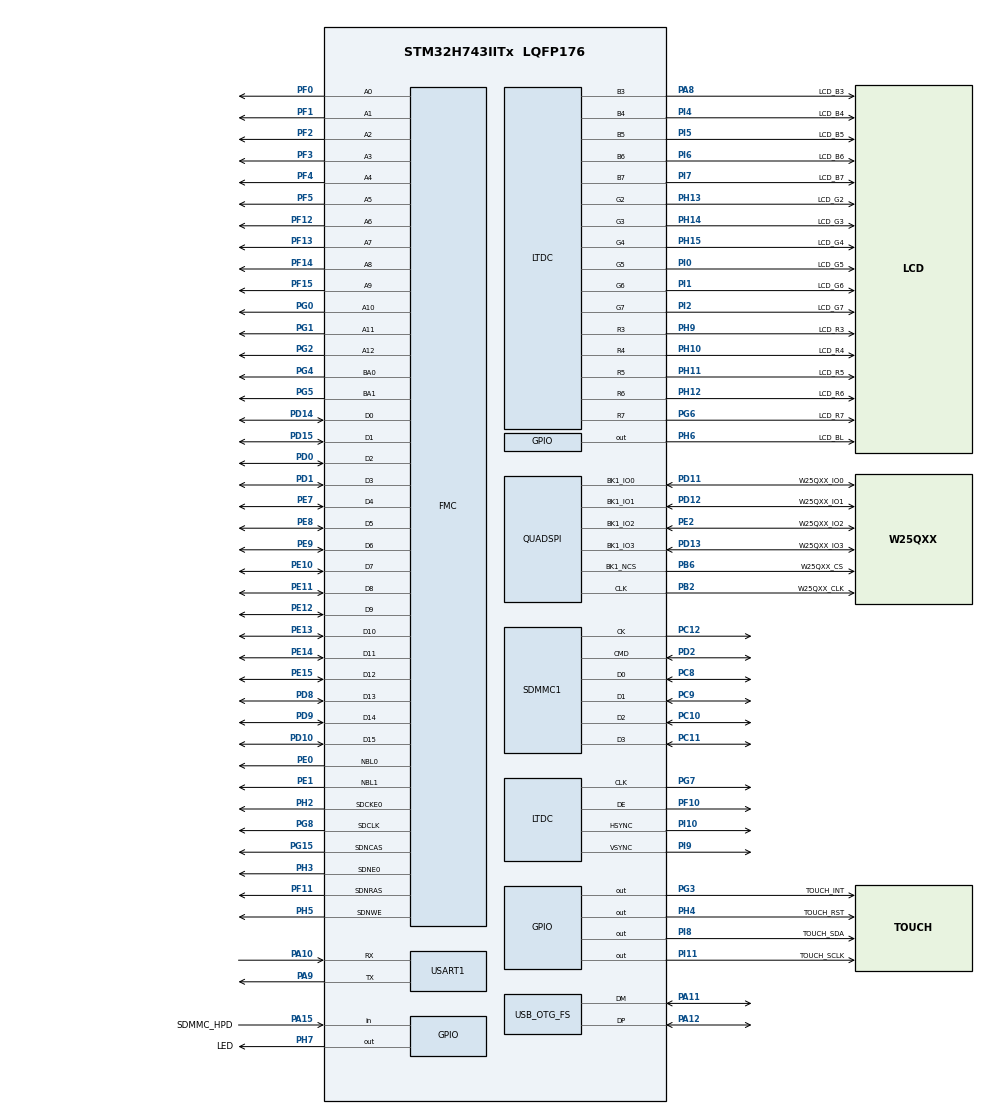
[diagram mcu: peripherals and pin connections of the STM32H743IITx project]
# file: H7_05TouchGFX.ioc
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CORTEX_M7.AccessPermission-Cortex_Memory_Protection_Unit_Region0_Settings=MPU_REGION_FULL_ACCESS
CORTEX_M7.BaseAddress-Cortex_Memory_Protection_Unit_Region0_Settings=0x38000000
CORTEX_M7.CPU_DCache=Enabled
CORTEX_M7.CPU_ICache=Enabled
CORTEX_M7.DisableExec-Cortex_Memory_Protection_Unit_Region0_Settings=MPU_INSTRUCTION_ACCESS_ENABLE
CORTEX_M7.Enable-Cortex_Memory_Protection_Unit_Region0_Settings=MPU_REGION_ENABLE
CORTEX_M7.IsCacheable-Cortex_Memory_Protection_Unit_Region0_Settings=MPU_ACCESS_CACHEABLE
CORTEX_M7.IsShareable-Cortex_Memory_Protection_Unit_Region0_Settings=MPU_ACCESS_SHAREABLE
CORTEX_M7.MPU_Control=MPU_PRIVILEGED_DEFAULT
CORTEX_M7.Size-Cortex_Memory_Protection_Unit_Region0_Settings=MPU_REGION_SIZE_64KB
DMA2D.ColorMode=DMA2D_OUTPUT_RGB565
DMA2D.InputColorModeForeground=DMA2D_INPUT_RGB565
DMA2D.Mode=DMA2D_M2M
Dma.Request0=USART1_RX
Dma.USART1_RX.0.Direction=DMA_PERIPH_TO_MEMORY
Dma.USART1_RX.0.EventEnable=DISABLE
Dma.USART1_RX.0.FIFOMode=DMA_FIFOMODE_DISABLE
Dma.USART1_RX.0.Instance=DMA1_Stream0
Dma.USART1_RX.0.MemDataAlignment=DMA_MDATAALIGN_BYTE
Dma.USART1_RX.0.MemInc=DMA_MINC_ENABLE
Dma.USART1_RX.0.Mode=DMA_NORMAL
Dma.USART1_RX.0.PeriphDataAlignment=DMA_PDATAALIGN_BYTE
Dma.USART1_RX.0.PeriphInc=DMA_PINC_DISABLE
Dma.USART1_RX.0.Polarity=HAL_DMAMUX_REQ_GEN_RISING
Dma.USART1_RX.0.Priority=DMA_PRIORITY_LOW
Dma.USART1_RX.0.RequestNumber=1
Dma.USART1_RX.0.SignalID=NONE
Dma.USART1_RX.0.SyncEnable=DISABLE
Dma.USART1_RX.0.SyncPolarity=HAL_DMAMUX_SYNC_NO_EVENT
Dma.USART1_RX.0.SyncRequestNumber=1
Dma.USART1_RX.0.SyncSignalID=NONE
FATFS.BSP.number=1
FATFS._CODE_PAGE=437
FATFS._FS_LOCK=0
FATFS._FS_NORTC=1
FATFS._MAX_SS=4096
FATFS._NORTC_MDAY=5
FATFS._NORTC_MON=1
FATFS._NORTC_YEAR=2017
FATFS._USE_FASTSEEK=0
FATFS._USE_LFN=2
FATFS._USE_STRFUNC=0
FATFS._VOLUMES=1
FATFS0.BSP.STBoard=false
FATFS0.BSP.api=Unknown
FATFS0.BSP.i2caddr=0
FATFS0.BSP.instance=PA15 (JTDI)
FATFS0.BSP.ip=GPIO
FATFS0.BSP.mode=Input
FATFS0.BSP.name=Detect_SDIO
FATFS0.BSP.solution=PA15 (JTDI)
FMC.BankMapConfig=FMC_SWAPBMAP_DISABLE
FMC.CASLatency1=FMC_SDRAM_CAS_LATENCY_3
FMC.ColumnBitsNumber1=FMC_SDRAM_COLUMN_BITS_NUM_9
FMC.ExitSelfRefreshDelay1=7
FMC.LoadToActiveDelay1=2
FMC.RCDDelay1=2
FMC.RPDelay1=2
FMC.ReadBurst1=FMC_SDRAM_RBURST_ENABLE
FMC.ReadPipeDelay1=FMC_SDRAM_RPIPE_DELAY_1
FMC.RowCycleDelay1=7
FMC.SDClockPeriod1=FMC_SDRAM_CLOCK_PERIOD_2
FMC.SelfRefreshTime1=4
FMC.WriteRecoveryTime1=3
FREERTOS.Tasks01=defaultTask,24,5120,StartDefaultTask,Default,NULL,Dynamic,NULL,NULL
FREERTOS.configGENERATE_RUN_TIME_STATS=1
FREERTOS.configRECORD_STACK_HIGH_ADDRESS=1
FREERTOS.configTOTAL_HEAP_SIZE=131072
FREERTOS.configUSE_NEWLIB_REENTRANT=1
FREERTOS.configUSE_STATS_FORMATTING_FUNCTIONS=1
LTDC.ActiveH=480
LTDC.ActiveW=800
LTDC.Alpha_L0=0xFF
LTDC.BlendingFactor1_L0=LTDC_BLENDING_FACTOR1_CA
LTDC.BlendingFactor2_L0=LTDC_BLENDING_FACTOR2_CA
LTDC.FBStartAdress_L0=0xC0000000
LTDC.HBP=80
LTDC.HFP=200
LTDC.HSync=1
LTDC.ImageHeight_L0=480
LTDC.ImageWidth_L0=800
LTDC.Layers=0
LTDC.PixelFormat_L0=LTDC_PIXEL_FORMAT_RGB565
LTDC.VBP=40
LTDC.VFP=22
LTDC.VSync=1
LTDC.WindowX1_L0=800
LTDC.WindowY1_L0=480
Mcu.Family=STM32H7
Mcu.Name=STM32H743IITx
Mcu.Package=LQFP176
NVIC.DMA1_Stream0_IRQn=true\:5\:0\:false\:false\:true\:true\:false\:true
NVIC.LTDC_IRQn=true\:5\:0\:false\:false\:true\:true\:true\:true
NVIC.OTG_FS_IRQn=true\:5\:0\:false\:false\:true\:true\:true\:true
NVIC.PriorityGroup=NVIC_PRIORITYGROUP_4
NVIC.TIM6_DAC_IRQn=true\:5\:0\:false\:false\:false\:true\:true\:true
NVIC.TIM7_IRQn=true\:15\:0\:false\:false\:true\:false\:false\:true
NVIC.TimeBase=TIM7_IRQn
NVIC.TimeBaseIP=TIM7
NVIC.USART1_IRQn=true\:6\:0\:true\:false\:false\:true\:true\:false
PA10.Mode=Asynchronous
PA10.Signal=USART1_RX
PA11.Mode=Device_Only
PA11.Signal=USB_OTG_FS_DM
PA12.Mode=Device_Only
PA12.Signal=USB_OTG_FS_DP
PA13\ (JTMS/SWDIO).Mode=Serial_Wire
PA13\ (JTMS/SWDIO).Signal=DEBUG_JTMS-SWDIO
PA14\ (JTCK/SWCLK).Mode=Serial_Wire
PA14\ (JTCK/SWCLK).Signal=DEBUG_JTCK-SWCLK
PA15\ (JTDI).GPIO_Label=SDMMC_HPD
PA15\ (JTDI).GPIO_PuPd=GPIO_PULLDOWN
PA15\ (JTDI).Signal=GPIO_Input
PA2.GPIO_Label=LCD_R1
PA2.GPIO_Speed=GPIO_SPEED_FREQ_VERY_HIGH
PA2.Signal=LTDC_R1
PA8.GPIO_Label=LCD_B3
PA8.GPIO_Speed=GPIO_SPEED_FREQ_VERY_HIGH
PA8.Mode=RGB565
PA8.Signal=LTDC_B3
PA9.Mode=Asynchronous
PA9.Signal=USART1_TX
PB2.GPIO_Label=W25QXX_CLK
PB2.GPIO_Speed=GPIO_SPEED_FREQ_VERY_HIGH
PB2.Mode=Single Bank 1
PB2.Signal=QUADSPI_CLK
PB6.GPIO_FM6=SYSCFG_PMCR_I2C_PB6_FMP
PB6.GPIO_Label=W25QXX_CS
PB6.GPIO_Speed=GPIO_SPEED_FREQ_VERY_HIGH
PB6.Mode=Single Bank 1
PB6.Signal=QUADSPI_BK1_NCS
PC10.Mode=SD_4_bits_Wide_bus
PC10.Signal=SDMMC1_D2
PC11.Mode=SD_4_bits_Wide_bus
PC11.Signal=SDMMC1_D3
PC12.Mode=SD_4_bits_Wide_bus
PC12.Signal=SDMMC1_CK
PC14-OSC32_IN\ (OSC32_IN).Mode=LSE-External-Oscillator
PC14-OSC32_IN\ (OSC32_IN).Signal=RCC_OSC32_IN
PC15-OSC32_OUT\ (OSC32_OUT).Mode=LSE-External-Oscillator
PC15-OSC32_OUT\ (OSC32_OUT).Signal=RCC_OSC32_OUT
PC8.Mode=SD_4_bits_Wide_bus
PC8.Signal=SDMMC1_D0
PC9.Mode=SD_4_bits_Wide_bus
PC9.Signal=SDMMC1_D1
PD0.Signal=FMC_D2_DA2
PD1.Signal=FMC_D3_DA3
PD10.Signal=FMC_D15_DA15
PD11.GPIO_Label=W25QXX_IO0
PD11.GPIO_Speed=GPIO_SPEED_FREQ_VERY_HIGH
PD11.Mode=Single Bank 1
PD11.Signal=QUADSPI_BK1_IO0
PD12.GPIO_Label=W25QXX_IO1
PD12.GPIO_Speed=GPIO_SPEED_FREQ_VERY_HIGH
PD12.Mode=Single Bank 1
PD12.Signal=QUADSPI_BK1_IO1
PD13.GPIO_Label=W25QXX_IO3
PD13.GPIO_Speed=GPIO_SPEED_FREQ_VERY_HIGH
PD13.Mode=Single Bank 1
PD13.Signal=QUADSPI_BK1_IO3
PD14.Signal=FMC_D0_DA0
PD15.Signal=FMC_D1_DA1
PD2.Mode=SD_4_bits_Wide_bus
PD2.Signal=SDMMC1_CMD
PD6.GPIO_Label=LCD_B2
PD6.GPIO_Speed=GPIO_SPEED_FREQ_VERY_HIGH
PD6.Signal=LTDC_B2
PD8.Signal=FMC_D13_DA13
PD9.Signal=FMC_D14_DA14
PE0.GPIO_Speed_High_Default=GPIO_SPEED_FREQ_VERY_HIGH
PE0.Signal=FMC_NBL0
PE1.Signal=FMC_NBL1
PE10.Signal=FMC_D7_DA7
PE11.Signal=FMC_D8_DA8
PE12.Signal=FMC_D9_DA9
PE13.Signal=FMC_D10_DA10
PE14.Signal=FMC_D11_DA11
PE15.Signal=FMC_D12_DA12
PE2.GPIO_Label=W25QXX_IO2
PE2.GPIO_Speed=GPIO_SPEED_FREQ_VERY_HIGH
PE2.Mode=Single Bank 1
PE2.Signal=QUADSPI_BK1_IO2
PE5.GPIO_Label=LCD_G0
PE5.GPIO_Speed=GPIO_SPEED_FREQ_VERY_HIGH
PE5.Signal=LTDC_G0
PE6.GPIO_Label=LCD_G1
PE6.GPIO_Speed=GPIO_SPEED_FREQ_VERY_HIGH
PE6.PinAttribute=Free
PE6.Signal=LTDC_G1
PE7.Signal=FMC_D4_DA4
PE8.Signal=FMC_D5_DA5
PE9.Signal=FMC_D6_DA6
PF0.Signal=FMC_A0
PF1.Signal=FMC_A1
PF10.GPIO_Speed=GPIO_SPEED_FREQ_VERY_HIGH
PF10.Mode=RGB565
PF10.Signal=LTDC_DE
PF11.Signal=FMC_SDNRAS
PF12.Signal=FMC_A6
PF13.Signal=FMC_A7
PF14.Signal=FMC_A8
PF15.Signal=FMC_A9
PF2.Signal=FMC_A2
PF3.Signal=FMC_A3
PF4.Signal=FMC_A4
PF5.Signal=FMC_A5
PG0.Signal=FMC_A10
PG1.Signal=FMC_A11
PG12.GPIO_Label=LCD_B1
PG12.GPIO_Speed=GPIO_SPEED_FREQ_VERY_HIGH
PG12.Signal=LTDC_B1
PG13.GPIO_Label=LCD_R0
PG13.GPIO_Speed=GPIO_SPEED_FREQ_VERY_HIGH
PG13.Signal=LTDC_R0
PG14.GPIO_Label=LCD_B0
PG14.GPIO_Speed=GPIO_SPEED_FREQ_VERY_HIGH
PG14.Signal=LTDC_B0
PG15.Signal=FMC_SDNCAS
PG2.Signal=FMC_A12
PG3.GPIO_Label=TOUCH_INT
PG3.GPIO_Speed=GPIO_SPEED_FREQ_LOW
PG3.Signal=GPIO_Output
PG4.Signal=FMC_A14_BA0
PG5.Signal=FMC_A15_BA1
PG6.GPIO_Label=LCD_R7
PG6.GPIO_Speed=GPIO_SPEED_FREQ_VERY_HIGH
PG6.Mode=RGB565
PG6.Signal=LTDC_R7
PG7.GPIO_Speed=GPIO_SPEED_FREQ_VERY_HIGH
PG7.Mode=RGB565
PG7.Signal=LTDC_CLK
PG8.Signal=FMC_SDCLK
PH0-OSC_IN\ (PH0).Mode=HSE-External-Oscillator
PH0-OSC_IN\ (PH0).Signal=RCC_OSC_IN
PH1-OSC_OUT\ (PH1).Mode=HSE-External-Oscillator
PH1-OSC_OUT\ (PH1).Signal=RCC_OSC_OUT
PH10.GPIO_Label=LCD_R4
PH10.GPIO_Speed=GPIO_SPEED_FREQ_VERY_HIGH
PH10.Mode=RGB565
PH10.Signal=LTDC_R4
PH11.GPIO_Label=LCD_R5
PH11.GPIO_Speed=GPIO_SPEED_FREQ_VERY_HIGH
PH11.Mode=RGB565
PH11.Signal=LTDC_R5
PH12.GPIO_Label=LCD_R6
PH12.GPIO_Speed=GPIO_SPEED_FREQ_VERY_HIGH
PH12.Mode=RGB565
PH12.Signal=LTDC_R6
PH13.GPIO_Label=LCD_G2
PH13.GPIO_Speed=GPIO_SPEED_FREQ_VERY_HIGH
PH13.Mode=RGB565
PH13.Signal=LTDC_G2
PH14.GPIO_Label=LCD_G3
PH14.GPIO_Speed=GPIO_SPEED_FREQ_VERY_HIGH
PH14.Mode=RGB565
PH14.Signal=LTDC_G3
PH15.GPIO_Label=LCD_G4
PH15.GPIO_Speed=GPIO_SPEED_FREQ_VERY_HIGH
PH15.Mode=RGB565
PH15.Signal=LTDC_G4
PH2.Mode=SdramChipSelect1_1
PH2.Signal=FMC_SDCKE0
PH3.Mode=SdramChipSelect1_1
PH3.Signal=FMC_SDNE0
PH4.GPIO_Label=TOUCH_RST
PH4.GPIO_PuPd=GPIO_NOPULL
PH4.GPIO_Speed=GPIO_SPEED_FREQ_LOW
PH4.PinState=GPIO_PIN_SET
PH4.Signal=GPIO_Output
PH5.Signal=FMC_SDNWE
PH6.GPIO_Label=LCD_BL
PH6.GPIO_PuPd=GPIO_NOPULL
PH6.PinState=GPIO_PIN_RESET
PH6.Signal=GPIO_Output
PH7.GPIO_Label=LED
PH7.GPIO_PuPd=GPIO_PULLUP
PH7.GPIO_Speed=GPIO_SPEED_FREQ_VERY_HIGH
PH7.Signal=GPIO_Output
PH8.GPIO_Label=LCD_R2
PH8.GPIO_Speed=GPIO_SPEED_FREQ_VERY_HIGH
PH8.Signal=LTDC_R2
PH9.GPIO_Label=LCD_R3
PH9.GPIO_Speed=GPIO_SPEED_FREQ_VERY_HIGH
PH9.Mode=RGB565
PH9.Signal=LTDC_R3
PI0.GPIO_Label=LCD_G5
PI0.GPIO_Speed=GPIO_SPEED_FREQ_VERY_HIGH
PI0.Mode=RGB565
PI0.Signal=LTDC_G5
PI1.GPIO_Label=LCD_G6
PI1.GPIO_Speed=GPIO_SPEED_FREQ_VERY_HIGH
PI1.Mode=RGB565
PI1.Signal=LTDC_G6
PI10.GPIO_Speed=GPIO_SPEED_FREQ_VERY_HIGH
PI10.Mode=RGB565
PI10.Signal=LTDC_HSYNC
PI11.GPIO_Label=TOUCH_SCLK
PI11.GPIO_ModeDefaultOutputPP=GPIO_MODE_OUTPUT_OD
PI11.GPIO_Speed=GPIO_SPEED_FREQ_LOW
PI11.Signal=GPIO_Output
PI2.GPIO_Label=LCD_G7
PI2.GPIO_Speed=GPIO_SPEED_FREQ_VERY_HIGH
PI2.Mode=RGB565
PI2.Signal=LTDC_G7
PI4.GPIO_Label=LCD_B4
PI4.GPIO_Speed=GPIO_SPEED_FREQ_VERY_HIGH
PI4.Mode=RGB565
PI4.Signal=LTDC_B4
PI5.GPIO_Label=LCD_B5
PI5.GPIO_Speed=GPIO_SPEED_FREQ_VERY_HIGH
PI5.Mode=RGB565
PI5.Signal=LTDC_B5
PI6.GPIO_Label=LCD_B6
PI6.GPIO_Speed=GPIO_SPEED_FREQ_VERY_HIGH
PI6.Mode=RGB565
PI6.Signal=LTDC_B6
PI7.GPIO_Label=LCD_B7
PI7.GPIO_Speed=GPIO_SPEED_FREQ_VERY_HIGH
PI7.Mode=RGB565
PI7.Signal=LTDC_B7
PI8.GPIO_Label=TOUCH_SDA
PI8.GPIO_ModeDefaultOutputPP=GPIO_MODE_OUTPUT_OD
PI8.GPIO_Speed=GPIO_SPEED_FREQ_LOW
PI8.PinAttribute=Free
PI8.Signal=GPIO_Output
PI9.GPIO_Speed=GPIO_SPEED_FREQ_VERY_HIGH
PI9.Mode=RGB565
PI9.Signal=LTDC_VSYNC
ProjectManager.HeapSize=0x2000
ProjectManager.StackSize=0x4000
ProjectManager.TargetToolchain=STM32CubeIDE
QUADSPI.ClockMode=QSPI_CLOCK_MODE_3
QUADSPI.ClockPrescaler=1
QUADSPI.FifoThreshold=32
QUADSPI.FlashSize=22
QUADSPI.SampleShifting=QSPI_SAMPLE_SHIFTING_HALFCYCLE
RCC.ADCFreq_Value=240000000
RCC.APB1Freq_Value=64000000
RCC.APB2Freq_Value=64000000
RCC.APB3Freq_Value=64000000
RCC.APB4Freq_Value=64000000
RCC.CortexFreq_Value=256000000
RCC.D1PPRE=RCC_APB3_DIV2
RCC.D2PPRE1=RCC_APB1_DIV2
RCC.D2PPRE2=RCC_APB2_DIV2
RCC.D3PPRE=RCC_APB4_DIV2
RCC.DIVM1=25
RCC.DIVM2=5
RCC.DIVM3=25
RCC.DIVN1=512
RCC.DIVN2=96
RCC.DIVN3=330
RCC.DIVQ1=16
RCC.DIVQ2=10
RCC.DIVR1=8
RCC.DIVR2=4
RCC.DIVR3=10
RCC.FMCCLockSelection=RCC_FMCCLKSOURCE_PLL2
RCC.HCLKFreq_Value=128000000
RCC.HPRE=RCC_HCLK_DIV2
RCC.PLL2FRACN=0
RCC.PLL3FRACN=0
RCC.PLL3_VCO_SEL=RCC_PLL3VCOMEDIUM
RCC.PLLSourceVirtual=RCC_PLLSOURCE_HSE
RCC.SYSCLKFreq_VALUE=256000000
RCC.SYSCLKSource=RCC_SYSCLKSOURCE_PLLCLK
RCC.USART16CLockSelection=RCC_USART16CLKSOURCE_PLL2
RCC.USBCLockSelection=RCC_USBCLKSOURCE_HSI48
RCC.USBFreq_Value=48000000
SDMMC1.ClockDiv=6
SH.FMC_A0.0=FMC_A0,13b-sda1
SH.FMC_A1.0=FMC_A1,13b-sda1
SH.FMC_A10.0=FMC_A10,13b-sda1
SH.FMC_A11.0=FMC_A11,13b-sda1
SH.FMC_A12.0=FMC_A12,13b-sda1
SH.FMC_A14_BA0.0=FMC_BA0,FourSdramBanks1
SH.FMC_A15_BA1.0=FMC_BA1,FourSdramBanks1
SH.FMC_A2.0=FMC_A2,13b-sda1
SH.FMC_A3.0=FMC_A3,13b-sda1
SH.FMC_A4.0=FMC_A4,13b-sda1
SH.FMC_A5.0=FMC_A5,13b-sda1
SH.FMC_A6.0=FMC_A6,13b-sda1
SH.FMC_A7.0=FMC_A7,13b-sda1
SH.FMC_A8.0=FMC_A8,13b-sda1
SH.FMC_A9.0=FMC_A9,13b-sda1
SH.FMC_D0_DA0.0=FMC_D0,sd-16b-d1
SH.FMC_D10_DA10.0=FMC_D10,sd-16b-d1
SH.FMC_D11_DA11.0=FMC_D11,sd-16b-d1
SH.FMC_D12_DA12.0=FMC_D12,sd-16b-d1
SH.FMC_D13_DA13.0=FMC_D13,sd-16b-d1
SH.FMC_D14_DA14.0=FMC_D14,sd-16b-d1
SH.FMC_D15_DA15.0=FMC_D15,sd-16b-d1
SH.FMC_D1_DA1.0=FMC_D1,sd-16b-d1
SH.FMC_D2_DA2.0=FMC_D2,sd-16b-d1
SH.FMC_D3_DA3.0=FMC_D3,sd-16b-d1
SH.FMC_D4_DA4.0=FMC_D4,sd-16b-d1
SH.FMC_D5_DA5.0=FMC_D5,sd-16b-d1
SH.FMC_D6_DA6.0=FMC_D6,sd-16b-d1
SH.FMC_D7_DA7.0=FMC_D7,sd-16b-d1
SH.FMC_D8_DA8.0=FMC_D8,sd-16b-d1
SH.FMC_D9_DA9.0=FMC_D9,sd-16b-d1
SH.FMC_NBL0.0=FMC_NBL0,Sd2ByteEnable1
SH.FMC_NBL1.0=FMC_NBL1,Sd2ByteEnable1
SH.FMC_SDCLK.0=FMC_SDCLK,13b-sda1
SH.FMC_SDNCAS.0=FMC_SDNCAS,13b-sda1
SH.FMC_SDNRAS.0=FMC_SDNRAS,13b-sda1
SH.FMC_SDNWE.0=FMC_SDNWE,13b-sda1
STMicroelectronics.X-CUBE-TOUCHGFX.4.18.0.ApplicationCcGraphicsJjApplication=TouchGFXOoGenerator
STMicroelectronics.X-CUBE-TOUCHGFX.4.18.0.tgfx_address1=0xC0000000
STMicroelectronics.X-CUBE-TOUCHGFX.4.18.0.tgfx_address2=0xC00BB800
STMicroelectronics.X-CUBE-TOUCHGFX.4.18.0.tgfx_buffering_strategy=Double
STMicroelectronics.X-CUBE-TOUCHGFX.4.18.0.tgfx_display_interface=disp_ltdc
STMicroelectronics.X-CUBE-TOUCHGFX.4.18.0.tgfx_hardware_accelerator=dma_2d
STMicroelectronics.X-CUBE-TOUCHGFX.4.18.0.tgfx_location=By Address
STMicroelectronics.X-CUBE-TOUCHGFX.4.18.0.tgfx_vsync=vsync_ltdc
STMicroelectronics.X-CUBE-TOUCHGFX.4.18.0_IsPackSelfContextualization=true
TIM6.Period=100-1
TIM6.Prescaler=128-1
USART1.VirtualMode-Asynchronous=VM_ASYNC
USB_DEVICE.CLASS_NAME_FS=MSC
USB_DEVICE.MSC_MEDIA_PACKET-MSC_FS=4096
USB_DEVICE.PID_MSC_FS=22313
USB_DEVICE.USBD_DEBUG_LEVEL-MSC_FS=3
USB_DEVICE.USBD_MAX_NUM_CONFIGURATION-MSC_FS=1
USB_DEVICE.USBD_MAX_NUM_INTERFACES-MSC_FS=1
USB_DEVICE.VID-MSC_FS=1154
USB_DEVICE.VirtualMode-MSC_FS=Msc
USB_DEVICE.VirtualModeFS=Msc_FS
USB_OTG_FS.VirtualMode=Device_Only
VP_CRC_VS_CRC.Mode=CRC_Activate
VP_DMA2D_VS_DMA2D.Mode=DMA2D_Activate
VP_FATFS_VS_SDIO.Mode=SDIO
VP_FREERTOS_VS_CMSIS_V2.Mode=CMSIS_V2
VP_STMicroelectronics.X-CUBE-TOUCHGFX_VS_GraphicsJjApplication_4.18.0.Mode=GraphicsJjApplication
VP_SYS_VS_tim7.Mode=TIM7
VP_TIM12_VS_ClockSourceINT.Mode=Internal
VP_TIM6_VS_ClockSourceINT.Mode=Enable_Timer
VP_USB_DEVICE_VS_USB_DEVICE_MSC_FS.Mode=MSC_FS
board=custom

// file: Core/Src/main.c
/* USER CODE BEGIN Header */
/**
  ******************************************************************************
  * @file           : main.c
  * @brief          : Main program body
  ******************************************************************************
  * @attention
  *
  * <h2><center>&copy; Copyright (c) 2021 STMicroelectronics.
  * All rights reserved.</center></h2>
  *
  * This software component is licensed by ST under BSD 3-Clause license,
  * the "License"; You may not use this file except in compliance with the
  * License. You may obtain a copy of the License at:
  *                        opensource.org/licenses/BSD-3-Clause
  *
  ******************************************************************************
  */
/* USER CODE END Header */
#include "main.h"
#include "cmsis_os.h"
#include "crc.h"
#include "dma.h"
#include "dma2d.h"
#include "fatfs.h"
#include "ltdc.h"
#include "quadspi.h"
#include "sdmmc.h"
#include "tim.h"
#include "usart.h"
#include "usb_device.h"
#include "gpio.h"
#include "fmc.h"
#include "app_touchgfx.h"

/* USER CODE BEGIN Includes */
#include "stdio.h"
#include "lcd_rgb.h"
#include "string.h"
#include "touch_800x480.h"
#include "W25QXX.h"
#include "usart.h"
/* USER CODE END Includes */

void SystemClock_Config(void);
void PeriphCommonClock_Config(void);
static void MPU_Config(void);
void MX_FREERTOS_Init(void);
/* USER CODE BEGIN PFP */
/********************************************** 变量定义 *******************************************/

FRESULT 	MyFile_Res;    // 操作结果
FATFS 		SD_FatFs; 		// 文件系统对象
char SDPath[4];			// SD卡逻辑驱动路径
FATFS 		sFLASH_FatFs; 					// 文件系统对象
BYTE 			sFLASH_ReadBuffer[1024];	//要读出的数据

/**************************************************************************************************/

//	函数：FatFs_Check
//	功能：进行FatFs文件系统的挂载
//
FIL MyFile;
void FatFs_Check(void)	//判断FatFs是否挂载成功，若没有创建FatFs则格式化SD卡
{
	BYTE work[_MAX_SS];

	FATFS_LinkDriver(&SD_Driver, SDPath);		// 初始化驱动
	MyFile_Res = f_mount(&SD_FatFs,"0:",1);	//	挂载SD卡

	if (MyFile_Res == FR_OK)	//判断是否挂载成功
	{
		printf("SD文件系统挂载成功\r\n");
	}
	else
	{
		printf("SD卡还未创建文件系统，即将格式化\r\n");

		MyFile_Res = f_mkfs("0:",FM_FAT32,0,work,sizeof work);		//格式化SD卡，FAT32，簇默认大小16K

		if (MyFile_Res == FR_OK)		//判断是否格式化成功
			printf("SD卡格式化成功！\r\n");
		else
			printf("格式化失败，请检查或更换SD卡！\r\n");
	}

	  FRESULT res; /* FatFs function common result code */
	  uint32_t byteswritten; /* File write/read counts */
	  uint8_t wtext[] = "stm32l476g_eval : This is STM32 working with FatFs and uSD diskio driver"; /* File write buffer */
  if(f_open(&MyFile, "liuyan.TXT", FA_CREATE_ALWAYS | FA_WRITE) == FR_OK)
  {
    /* Write data to the text file */
    res = f_write(&MyFile, wtext, sizeof(wtext), (void *)&byteswritten);

    if((byteswritten > 0) && (res == FR_OK))
    {
      /* Close the open text file */
      f_close(&MyFile);

      /* Open the text file object with read access */
      //f_mount(NULL, (TCHAR const*)SDPath, 0);
    }
  }
}
/* USER CODE END PFP */

/* USER CODE BEGIN 0 */
//int __io_putchar(int ch)
//{
//	HAL_UART_Transmit(&huart1, (uint8_t*)&ch, 1, 0xFFFFFFFF);
//	return ch;
//}
/* USER CODE END 0 */

int main(void)
{

  /* MPU Configuration--------------------------------------------------------*/
  MPU_Config();

  /* Enable I-Cache---------------------------------------------------------*/
  SCB_EnableICache();

  /* Enable D-Cache---------------------------------------------------------*/
  SCB_EnableDCache();

  /* MCU Configuration--------------------------------------------------------*/

  /* Reset of all peripherals, Initializes the Flash interface and the Systick. */
  HAL_Init();

  /* Configure the system clock */
  SystemClock_Config();

/* Configure the peripherals common clocks */
  PeriphCommonClock_Config();

  /* Initialize all configured peripherals */
  MX_GPIO_Init();
  MX_DMA_Init();
  MX_DMA2D_Init();
  MX_LTDC_Init();
  MX_FMC_Init();
  MX_TIM12_Init();
  MX_USART1_UART_Init();
  MX_SDMMC1_SD_Init();
  MX_QUADSPI_Init();
  MX_FATFS_Init();
  MX_CRC_Init();
  MX_TIM6_Init();
  MX_TouchGFX_Init();
  /* USER CODE BEGIN 2 */
  Touch_Init();

  /* USER CODE END 2 */

  /* Init scheduler */
  osKernelInitialize();  /* Call init function for freertos objects (in freertos.c) */
  MX_FREERTOS_Init();
  /* Start scheduler */
  osKernelStart();

  /* We should never get here as control is now taken by the scheduler */
  /* Infinite loop */
  while (1)
  {

  }
}

void SystemClock_Config(void)
{
  RCC_OscInitTypeDef RCC_OscInitStruct = {0};
  RCC_ClkInitTypeDef RCC_ClkInitStruct = {0};

  /** Supply configuration update enable
  */
  HAL_PWREx_ConfigSupply(PWR_LDO_SUPPLY);
  /** Configure the main internal regulator output voltage
  */
  __HAL_PWR_VOLTAGESCALING_CONFIG(PWR_REGULATOR_VOLTAGE_SCALE2);

  while(!__HAL_PWR_GET_FLAG(PWR_FLAG_VOSRDY)) {}
  /** Macro to configure the PLL clock source
  */
  __HAL_RCC_PLL_PLLSOURCE_CONFIG(RCC_PLLSOURCE_HSE);
  /** Initializes the RCC Oscillators according to the specified parameters
  * in the RCC_OscInitTypeDef structure.
  */
  RCC_OscInitStruct.OscillatorType = RCC_OSCILLATORTYPE_HSI48|RCC_OSCILLATORTYPE_HSE;
  RCC_OscInitStruct.HSEState = RCC_HSE_ON;
  RCC_OscInitStruct.HSI48State = RCC_HSI48_ON;
  RCC_OscInitStruct.PLL.PLLState = RCC_PLL_ON;
  RCC_OscInitStruct.PLL.PLLSource = RCC_PLLSOURCE_HSE;
  RCC_OscInitStruct.PLL.PLLM = 25;
  RCC_OscInitStruct.PLL.PLLN = 512;
  RCC_OscInitStruct.PLL.PLLP = 2;
  RCC_OscInitStruct.PLL.PLLQ = 16;
  RCC_OscInitStruct.PLL.PLLR = 8;
  RCC_OscInitStruct.PLL.PLLRGE = RCC_PLL1VCIRANGE_0;
  RCC_OscInitStruct.PLL.PLLVCOSEL = RCC_PLL1VCOWIDE;
  RCC_OscInitStruct.PLL.PLLFRACN = 0;
  if (HAL_RCC_OscConfig(&RCC_OscInitStruct) != HAL_OK)
  {
    Error_Handler();
  }
  /** Initializes the CPU, AHB and APB buses clocks
  */
  RCC_ClkInitStruct.ClockType = RCC_CLOCKTYPE_HCLK|RCC_CLOCKTYPE_SYSCLK
                              |RCC_CLOCKTYPE_PCLK1|RCC_CLOCKTYPE_PCLK2
                              |RCC_CLOCKTYPE_D3PCLK1|RCC_CLOCKTYPE_D1PCLK1;
  RCC_ClkInitStruct.SYSCLKSource = RCC_SYSCLKSOURCE_PLLCLK;
  RCC_ClkInitStruct.SYSCLKDivider = RCC_SYSCLK_DIV1;
  RCC_ClkInitStruct.AHBCLKDivider = RCC_HCLK_DIV2;
  RCC_ClkInitStruct.APB3CLKDivider = RCC_APB3_DIV2;
  RCC_ClkInitStruct.APB1CLKDivider = RCC_APB1_DIV2;
  RCC_ClkInitStruct.APB2CLKDivider = RCC_APB2_DIV2;
  RCC_ClkInitStruct.APB4CLKDivider = RCC_APB4_DIV2;

  if (HAL_RCC_ClockConfig(&RCC_ClkInitStruct, FLASH_LATENCY_2) != HAL_OK)
  {
    Error_Handler();
  }
}

void PeriphCommonClock_Config(void)
{
  RCC_PeriphCLKInitTypeDef PeriphClkInitStruct = {0};

  /** Initializes the peripherals clock
  */
  PeriphClkInitStruct.PeriphClockSelection = RCC_PERIPHCLK_FMC|RCC_PERIPHCLK_USART1;
  PeriphClkInitStruct.PLL2.PLL2M = 5;
  PeriphClkInitStruct.PLL2.PLL2N = 96;
  PeriphClkInitStruct.PLL2.PLL2P = 2;
  PeriphClkInitStruct.PLL2.PLL2Q = 10;
  PeriphClkInitStruct.PLL2.PLL2R = 4;
  PeriphClkInitStruct.PLL2.PLL2RGE = RCC_PLL2VCIRANGE_2;
  PeriphClkInitStruct.PLL2.PLL2VCOSEL = RCC_PLL2VCOWIDE;
  PeriphClkInitStruct.PLL2.PLL2FRACN = 0;
  PeriphClkInitStruct.FmcClockSelection = RCC_FMCCLKSOURCE_PLL2;
  PeriphClkInitStruct.Usart16ClockSelection = RCC_USART16CLKSOURCE_PLL2;
  if (HAL_RCCEx_PeriphCLKConfig(&PeriphClkInitStruct) != HAL_OK)
  {
    Error_Handler();
  }
}

/* MPU Configuration */

void MPU_Config(void)
{
  MPU_Region_InitTypeDef MPU_InitStruct = {0};

  /* Disables the MPU */
  HAL_MPU_Disable();
  /** Initializes and configures the Region and the memory to be protected
  */
  MPU_InitStruct.Enable = MPU_REGION_ENABLE;
  MPU_InitStruct.Number = MPU_REGION_NUMBER0;
  MPU_InitStruct.BaseAddress = 0x38000000;
  MPU_InitStruct.Size = MPU_REGION_SIZE_64KB;
  MPU_InitStruct.SubRegionDisable = 0x0;
  MPU_InitStruct.TypeExtField = MPU_TEX_LEVEL0;
  MPU_InitStruct.AccessPermission = MPU_REGION_FULL_ACCESS;
  MPU_InitStruct.DisableExec = MPU_INSTRUCTION_ACCESS_ENABLE;
  MPU_InitStruct.IsShareable = MPU_ACCESS_SHAREABLE;
  MPU_InitStruct.IsCacheable = MPU_ACCESS_CACHEABLE;
  MPU_InitStruct.IsBufferable = MPU_ACCESS_NOT_BUFFERABLE;

  HAL_MPU_ConfigRegion(&MPU_InitStruct);
  /* Enables the MPU */
  HAL_MPU_Enable(MPU_PRIVILEGED_DEFAULT);

}

void HAL_TIM_PeriodElapsedCallback(TIM_HandleTypeDef *htim)
{
  if (htim->Instance == TIM7) {
    HAL_IncTick();
  }
}

void Error_Handler(void)
{
  __disable_irq();
  while (1)
  {
  }
}

/************************ (C) COPYRIGHT STMicroelectronics *****END OF FILE****/

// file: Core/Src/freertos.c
/* USER CODE BEGIN Header */
/**
  ******************************************************************************
  * File Name          : freertos.c
  * Description        : Code for freertos applications
  ******************************************************************************
  * @attention
  *
  * <h2><center>&copy; Copyright (c) 2021 STMicroelectronics.
  * All rights reserved.</center></h2>
  *
  * This software component is licensed by ST under Ultimate Liberty license
  * SLA0044, the "License"; You may not use this file except in compliance with
  * the License. You may obtain a copy of the License at:
  *                             www.st.com/SLA0044
  *
  ******************************************************************************
  */
/* USER CODE END Header */

#include "FreeRTOS.h"
#include "task.h"
#include "main.h"
#include "cmsis_os.h"

/* USER CODE BEGIN Includes */
#include "app_touchgfx.h"
/* USER CODE END Includes */

/* Definitions for defaultTask */
osThreadId_t defaultTaskHandle;
const osThreadAttr_t defaultTask_attributes = {
  .name = "defaultTask",
  .stack_size = 5120 * 4,
  .priority = (osPriority_t) osPriorityNormal,
};

void StartDefaultTask(void *argument);

extern void MX_USB_DEVICE_Init(void);
void MX_FREERTOS_Init(void); /* (MISRA C 2004 rule 8.1) */

/* Hook prototypes */
void configureTimerForRunTimeStats(void);
unsigned long getRunTimeCounterValue(void);

/* USER CODE BEGIN 1 */
/* Functions needed when configGENERATE_RUN_TIME_STATS is on */
__weak void configureTimerForRunTimeStats(void)
{

}

__weak unsigned long getRunTimeCounterValue(void)
{
return 0;
}
/* USER CODE END 1 */

void MX_FREERTOS_Init(void) {
  /* USER CODE BEGIN Init */
  extern void vUARTCommandConsoleStart( uint16_t usStackSize, UBaseType_t uxPriority );
  extern void vRegisterSampleCLICommands( void );
  extern void vRegisterMineCommands(void);
  //vRegisterSampleCLICommands();
  vRegisterMineCommands();
  vUARTCommandConsoleStart(4096,osPriorityBelowNormal);
  /* USER CODE END Init */

  /* Create the thread(s) */
  /* creation of defaultTask */
  defaultTaskHandle = osThreadNew(StartDefaultTask, NULL, &defaultTask_attributes);

  /* USER CODE BEGIN RTOS_THREADS */
  /* add threads, ... */
  extern void mytask_creat(void);
  mytask_creat();
  /* USER CODE END RTOS_THREADS */

}

void StartDefaultTask(void *argument)
{
  /* init code for USB_DEVICE */
  MX_USB_DEVICE_Init();
  /* USER CODE BEGIN StartDefaultTask */
  /* Infinite loop */
  for(;;)
  {
    MX_TouchGFX_Process();
    osDelay(1);
  }
  /* USER CODE END StartDefaultTask */
}

/************************ (C) COPYRIGHT STMicroelectronics *****END OF FILE****/
